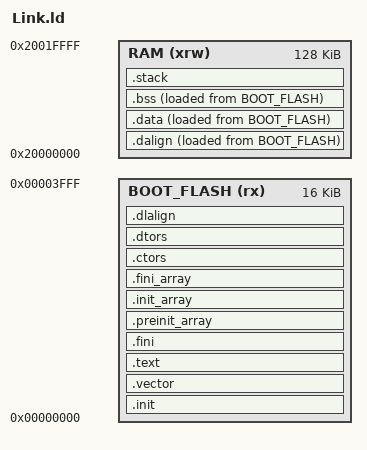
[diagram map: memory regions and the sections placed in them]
ENTRY( _start )

__stack_size = 2048;

PROVIDE( _stack_size = __stack_size );


/* Target chip option byte: SRAM_CODE_MODE = 00
 *   FLASH = 192K total, RAM = 128K.
 * Bootloader occupies the first 16K of flash (BOOT_FLASH).
 * The application is linked at 0x00004000 with the remaining 176K
 * (see firmware/Ld/Link.ld).
 *
 * Reference: CH32FV2x_V3xRM.PDF / Table 32-3, CH32V30x_D8 family
 * (CH32V303VC/RC).
 */
MEMORY
{
	BOOT_FLASH (rx) : ORIGIN = 0x00000000, LENGTH = 16K
	RAM        (xrw): ORIGIN = 0x20000000, LENGTH = 128K
}

/* End of total on-chip flash (exclusive). Used by the IAP code in
 * Bootloader/User/Host_IAP to know the upper bound for app programming.
 * Must match the FLASH size selected by SRAM_CODE_MODE above. */
PROVIDE(_flash_limit = 0x00000000 + 192K);

SECTIONS
{
	.init :
	{
		_sinit = .;
		. = ALIGN(4);
		KEEP(*(SORT_NONE(.init)))
		. = ALIGN(4);
		_einit = .;
	} >BOOT_FLASH AT>BOOT_FLASH

  .vector :
  {
      *(.vector);
	  . = ALIGN(64);
	} >BOOT_FLASH AT>BOOT_FLASH

	.text :
	{
		. = ALIGN(4);
		*(.text)
		*(.text.*)
		*(.rodata)
		*(.rodata*)
		*(.gnu.linkonce.t.*)
		. = ALIGN(4);
	} >BOOT_FLASH AT>BOOT_FLASH 

	.fini :
	{
		KEEP(*(SORT_NONE(.fini)))
		. = ALIGN(4);
	} >BOOT_FLASH AT>BOOT_FLASH

	PROVIDE( _etext = . );
	PROVIDE( _eitcm = . );	

	.preinit_array  :
	{
	  PROVIDE_HIDDEN (__preinit_array_start = .);
	  KEEP (*(.preinit_array))
	  PROVIDE_HIDDEN (__preinit_array_end = .);
	} >BOOT_FLASH AT>BOOT_FLASH 
	
	.init_array     :
	{
	  PROVIDE_HIDDEN (__init_array_start = .);
	  KEEP (*(SORT_BY_INIT_PRIORITY(.init_array.*) SORT_BY_INIT_PRIORITY(.ctors.*)))
	  KEEP (*(.init_array EXCLUDE_FILE (*crtbegin.o *crtbegin?.o *crtend.o *crtend?.o ) .ctors))
	  PROVIDE_HIDDEN (__init_array_end = .);
	} >BOOT_FLASH AT>BOOT_FLASH 
	
	.fini_array     :
	{
	  PROVIDE_HIDDEN (__fini_array_start = .);
	  KEEP (*(SORT_BY_INIT_PRIORITY(.fini_array.*) SORT_BY_INIT_PRIORITY(.dtors.*)))
	  KEEP (*(.fini_array EXCLUDE_FILE (*crtbegin.o *crtbegin?.o *crtend.o *crtend?.o ) .dtors))
	  PROVIDE_HIDDEN (__fini_array_end = .);
	} >BOOT_FLASH AT>BOOT_FLASH 
	
	.ctors          :
	{
	  /* gcc uses crtbegin.o to find the start of
	     the constructors, so we make sure it is
	     first.  Because this is a wildcard, it
	     doesn't matter if the user does not
	     actually link against crtbegin.o; the
	     linker won't look for a file to match a
	     wildcard.  The wildcard also means that it
	     doesn't matter which directory crtbegin.o
	     is in.  */
	  KEEP (*crtbegin.o(.ctors))
	  KEEP (*crtbegin?.o(.ctors))
	  /* We don't want to include the .ctor section from
	     the crtend.o file until after the sorted ctors.
	     The .ctor section from the crtend file contains the
	     end of ctors marker and it must be last */
	  KEEP (*(EXCLUDE_FILE (*crtend.o *crtend?.o ) .ctors))
	  KEEP (*(SORT(.ctors.*)))
	  KEEP (*(.ctors))
	} >BOOT_FLASH AT>BOOT_FLASH 
	
	.dtors          :
	{
	  KEEP (*crtbegin.o(.dtors))
	  KEEP (*crtbegin?.o(.dtors))
	  KEEP (*(EXCLUDE_FILE (*crtend.o *crtend?.o ) .dtors))
	  KEEP (*(SORT(.dtors.*)))
	  KEEP (*(.dtors))
	} >BOOT_FLASH AT>BOOT_FLASH 

	/* End of reserved bootloader region (matches app link base at 0x00004000). */
	PROVIDE(_bootloader_limit = ORIGIN(BOOT_FLASH) + LENGTH(BOOT_FLASH));

	.dalign :
	{
		. = ALIGN(4);
		PROVIDE(_data_vma = .);
	} >RAM AT>BOOT_FLASH	

	.dlalign :
	{
		. = ALIGN(4); 
		PROVIDE(_data_lma = .);
	} >BOOT_FLASH AT>BOOT_FLASH

	.data :
	{
    	*(.gnu.linkonce.r.*)
    	*(.data .data.*)
    	*(.gnu.linkonce.d.*)
		. = ALIGN(8);
    	PROVIDE( __global_pointer$ = . + 0x800 );
    	*(.sdata .sdata.*)
		*(.sdata2.*)
    	*(.gnu.linkonce.s.*)
    	. = ALIGN(8);
    	*(.srodata.cst16)
    	*(.srodata.cst8)
    	*(.srodata.cst4)
    	*(.srodata.cst2)
    	*(.srodata .srodata.*)
    	. = ALIGN(4);
		PROVIDE( _edata = .);
	} >RAM AT>BOOT_FLASH

	.bss :
	{
		. = ALIGN(4);
		PROVIDE( _sbss = .);
  	    *(.sbss*)
        *(.gnu.linkonce.sb.*)
		*(.bss*)
     	*(.gnu.linkonce.b.*)		
		*(COMMON*)
		. = ALIGN(4);
		PROVIDE( _ebss = .);
	} >RAM AT>BOOT_FLASH

	PROVIDE( _end = _ebss);
	PROVIDE( end = . );

    .stack ORIGIN(RAM) + LENGTH(RAM) - __stack_size :
    {
        PROVIDE( _heap_end = . );    
        . = ALIGN(4);
        PROVIDE(_susrstack = . );
        . = . + __stack_size;
        PROVIDE( _eusrstack = .);
    } >RAM 

}



